# MSP430FR2433 register map
Vendor: msp430gen; File version: v0.4.0-29-g702f6f3-dirty
Registers are 16-bit, read-write, reset 0x0 unless marked. A register's access mark holds for its fields unless they carry their own. Offsets are from the block's base; [hi:lo] are bit positions; {n}, {i} and the like mark numbered series.

## P2 — Port 2
Base 0x00000200
0x01 P2IN 8-bit — Port 2 Input register
0x03 P2OUT 8-bit — Port 2 Output register
0x05 P2DIR 8-bit — Port 2 Direction register
0x07 P2REN 8-bit — Port 2 Resistor Enable register
0x0B P2SEL0 8-bit — Port 2 Selection register bit 0
0x0D P2SEL1 8-bit — Port 2 Selection register bit 1
0x17 P2SELC 8-bit — Port 2 Complement Select register
0x19 P2IES 8-bit — Port 2 Interrupt Edge Select register
0x1B P2IE 8-bit — Port 2 Interrupt Enable register
0x1D P2IFG 8-bit — Port 2 Interrupt Flag register
0x1E P2IV — Port 2 Interrupt Vector register
  [15:0] P2IV
    0=NONE (No interrupt pending); 2=IFG0 (Interrupt Source: Port 2.0 interrupt; Interrupt Flag: P2IFG0; Interrupt Priority: Highest); 4=IFG1 (Interrupt Source: Port 2.1 interrupt; Interrupt Flag: P2IFG1); 6=IFG2 (Interrupt Source: Port 2.2 interrupt; Interrupt Flag: P2IFG2); 8=IFG3 (Interrupt Source: Port 2.3 interrupt; Interrupt Flag: P2IFG3); 10=IFG4 (Interrupt Source: Port 2.4 interrupt; Interrupt Flag: P2IFG4); 12=IFG5 (Interrupt Source: Port 2.5 interrupt; Interrupt Flag: P2IFG5); 14=IFG6 (Interrupt Source: Port 2.6 interrupt; Interrupt Flag: P2IFG6); 16=IFG7 (Interrupt Source: Port 2.7 interrupt; Interrupt Flag: P2IFG7; Interrupt Priority: Lowest)

## RTC
Base 0x00000300
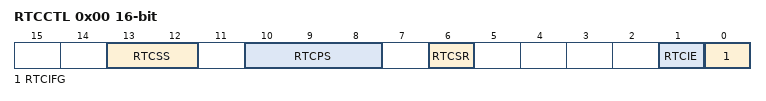
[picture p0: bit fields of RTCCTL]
0x00 RTCCTL — RTC control Register
  [13:12] RTCSS — Low-Power-Counter Clock Source Select Bit: 0
    0=DISABLED (Low-Power-Counter Clock Source Select: Disabled); 1=SMCLK (Low-Power-Counter Clock Source Select: SMCLK); 2=XT1CLK (Low-Power-Counter Clock Source Select: XT1CLK); 3=VLOCLK (Low-Power-Counter Clock Source Select: VLOCLK)
  [10:8] RTCPS — Low-Power-Counter Clock Pre-divider Select Bit: 0
    0=/1 (RTC Predivider /1); 1=/10 (RTC Predivider /10); 2=/100 (RTC Predivider /100); 3=/1000 (RTC Predivider /1000); 4=/16 (RTC Predivider /16); 5=/64 (RTC Predivider /64); 6=/256 (RTC Predivider /256); 7=/1024 (RTC Predivider /1024)
  [6] RTCSR — Low-Power-Counter Software Reset
  [1] RTCIE — Low-Power-Counter Interrupt Enable
  [0] RTCIFG — Low-Power-Counter Interrupt Flag
0x04 RTCIV — RTC interrupt vector
0x08 RTCMOD — RTC moduloRegister
0x0C RTCCNT — RTC counter Register

## TA0
Base 0x00000380
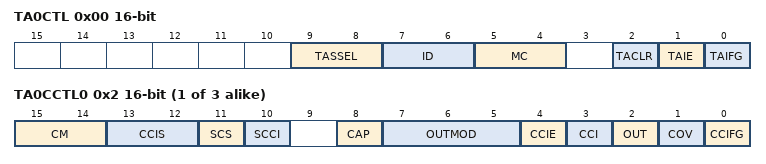
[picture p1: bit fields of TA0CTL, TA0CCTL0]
0x00 TA0CTL — Timer0_A3 Control
  [9:8] TASSEL — Timer A clock source select 1
    0=TACLK (TAxCLK); 1=ACLK; 2=SMCLK; 3=INCLK
  [7:6] ID — Timer A clock input divider 1
    0=/1; 1=/2; 2=/4; 3=/8
  [5:4] MC — Timer A mode control 1
    0=STOP (Stop mode: Timer is halted); 1=UP (Up mode: Timer counts up to TAxCCR0); 2=CONTINUOUS (Continuous mode: Timer counts up to 0FFFFh); 3=UPDOWN (Up/down mode: Timer counts up to TAxCCR0 then down to 0000h)
  [2] TACLR — Timer A counter clear
  [1] TAIE — Timer A counter interrupt enable
  [0] TAIFG — Timer A counter interrupt flag
{0x2+2i} TA0CCTL{i} (i=0..2) — Timer0_A3 Capture/Compare Control {i}
  [15:14] CM — Capture mode 1
    0=NONE (No capture); 1=RISING (Capture on rising edge); 2=FALLING (Capture on falling edge); 3=BOTH (Capture on both rising and falling edges)
  [13:12] CCIS — Capture input select 1
    0=CCIA (CCIxA); 1=CCIB (CCIxB); 2=GND; 3=VCC
  [11] SCS — Capture synchronize
  [10] SCCI — Latched capture signal (read)
  [8] CAP — Capture mode: 1 /Compare mode : 0
  [7:5] OUTMOD — Output mode 2
    0=PWM output mode: 0 - output only; 1=PWM output mode: 1 - set; 2=PWM output mode: 2 - PWM toggle/reset; 3=PWM output mode: 3 - PWM set/reset; 4=PWM output mode: 4 - toggle; 5=PWM output mode: 5 - Reset; 6=PWM output mode: 6 - PWM toggle/set; 7=PWM output mode: 7 - PWM reset/set
  [4] CCIE — Capture/compare interrupt enable
  [3] CCI — Capture input signal (read)
  [2] OUT — PWM Output signal if output mode 0
  [1] COV — Capture/compare overflow flag
  [0] CCIFG — Capture/compare interrupt flag
0x10 TA0R — Timer0_A3
{0x12+2i} TA0CCR{i} (i=0..2) — Timer0_A3 Capture/Compare {i}
0x20 TA0EX0 — Timer0_A3 Expansion Register 0
  [2:0] TAIDEX — Timer A Input divider expansion Bit: 0
    {v}=/{v+1} (Divide by {v+1}) (v=0..7)
0x2E TA0IV — Timer0_A3 Interrupt Vector Word
  [15:0] TAIV ro — Timer_A interrupt vector value
    0=NONE (No interrupt pending); 2=TACCR1 (Interrupt Source: Capture/compare 1; Interrupt Flag: TAxCCR1 CCIFG; Interrupt Priority: Highest); 4=TACCR2 (Interrupt Source: Capture/compare 2; Interrupt Flag: TAxCCR2 CCIFG); 6=TACCR3 (Interrupt Source: Capture/compare 3; Interrupt Flag: TAxCCR3 CCIFG); 8=TACCR4 (Interrupt Source: Capture/compare 4; Interrupt Flag: TAxCCR4 CCIFG); 10=TACCR5 (Interrupt Source: Capture/compare 5; Interrupt Flag: TAxCCR5 CCIFG); 12=TACCR6 (Interrupt Source: Capture/compare 6; Interrupt Flag: TAxCCR6 CCIFG); 14=TAIFG (Interrupt Source: Timer overflow; Interrupt Flag: TAxCTL TAIFG; Interrupt Priority: Lowest)
